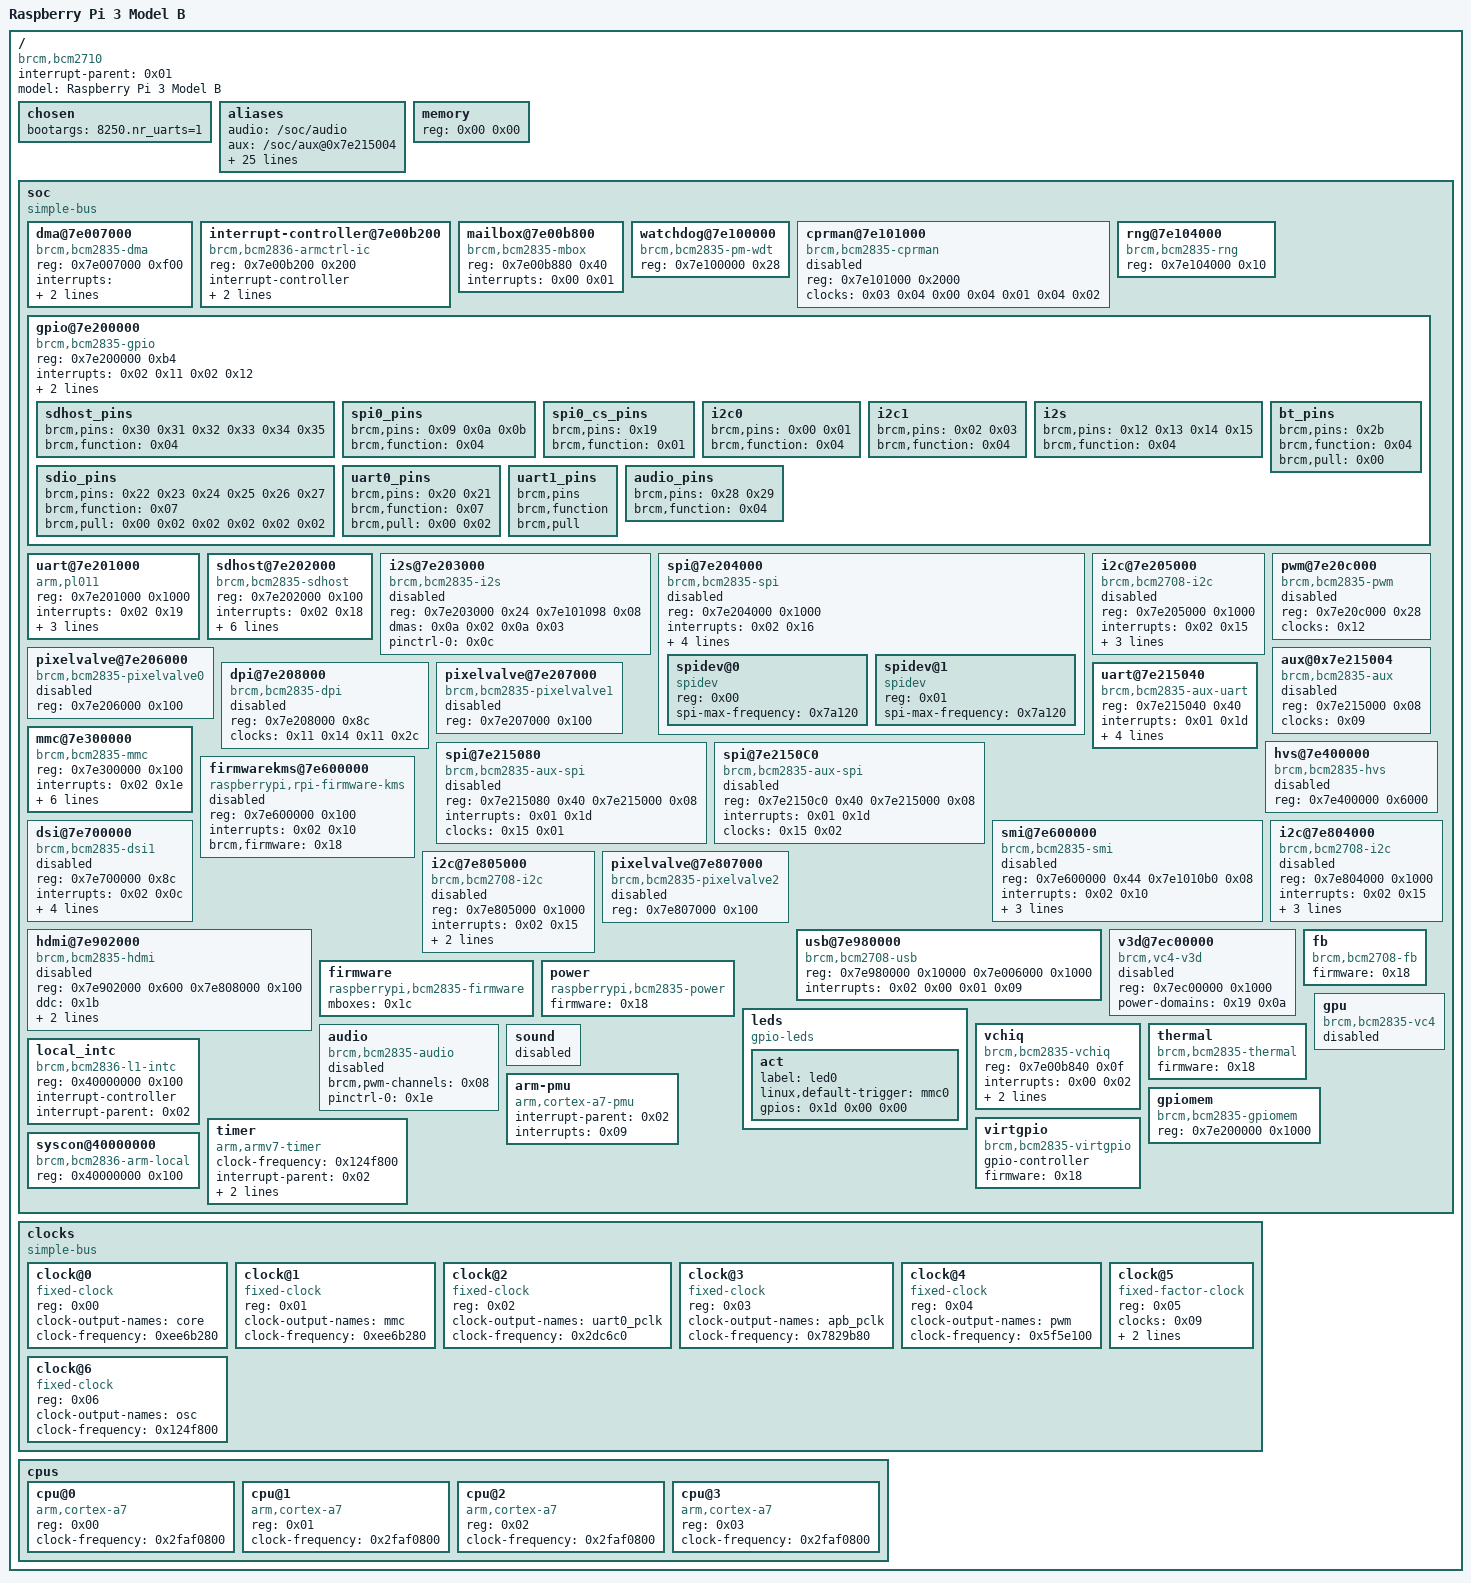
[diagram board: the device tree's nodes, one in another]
/dts-v1/;

/ {
	#address-cells = <0x01>;
	#size-cells = <0x01>;
	interrupt-parent = <0x01>;
	compatible = "brcm,bcm2710\0brcm,bcm2709";
	model = "Raspberry Pi 3 Model B";

	chosen {
		bootargs = "8250.nr_uarts=1";
	};

	aliases {
		audio = "/soc/audio";
		aux = "/soc/aux@0x7e215004";
		sound = "/soc/sound";
		soc = "/soc";
		dma = "/soc/dma@7e007000";
		intc = "/soc/interrupt-controller@7e00b200";
		watchdog = "/soc/watchdog@7e100000";
		random = "/soc/rng@7e104000";
		mailbox = "/soc/mailbox@7e00b800";
		gpio = "/soc/gpio@7e200000";
		uart0 = "/soc/uart@7e201000";
		sdhost = "/soc/sdhost@7e202000";
		i2s = "/soc/i2s@7e203000";
		spi0 = "/soc/spi@7e204000";
		i2c0 = "/soc/i2c@7e205000";
		uart1 = "/soc/uart@7e215040";
		spi1 = "/soc/spi@7e215080";
		spi2 = "/soc/spi@7e2150C0";
		mmc = "/soc/mmc@7e300000";
		i2c1 = "/soc/i2c@7e804000";
		i2c2 = "/soc/i2c@7e805000";
		usb = "/soc/usb@7e980000";
		leds = "/soc/leds";
		fb = "/soc/fb";
		vchiq = "/soc/vchiq";
		thermal = "/soc/thermal";
		clocks = "/clocks";
	};

	memory {
		device_type = "memory";
		reg = <0x00 0x00>;
	};

	soc {
		compatible = "simple-bus";
		#address-cells = <0x01>;
		#size-cells = <0x01>;
		ranges = <0x7e000000 0x3f000000 0x1000000 0x40000000 0x40000000 0x40000>;
		phandle = <0x2f>;

		dma@7e007000 {
			compatible = "brcm,bcm2835-dma";
			reg = <0x7e007000 0xf00>;
			interrupts = <0x01 0x10 0x01 0x11 0x01 0x12 0x01 0x13 0x01 0x14 0x01 0x15 0x01 0x16 0x01 0x17 0x01 0x18 0x01 0x19 0x01 0x1a 0x01 0x1b 0x01 0x1b 0x01 0x1b 0x01 0x1b 0x01 0x1c>;
			interrupt-names = "dma0\0dma1\0dma2\0dma3\0dma4\0dma5\0dma6\0dma7\0dma8\0dma9\0dma10\0dma11\0dma12\0dma13\0dma14\0dma-shared-all";
			#dma-cells = <0x01>;
			brcm,dma-channel-mask = <0x7f34>;
			phandle = <0x0a>;
		};

		interrupt-controller@7e00b200 {
			compatible = "brcm,bcm2836-armctrl-ic";
			reg = <0x7e00b200 0x200>;
			interrupt-controller;
			#interrupt-cells = <0x02>;
			interrupt-parent = <0x02>;
			interrupts = <0x08>;
			phandle = <0x01>;
		};

		mailbox@7e00b800 {
			compatible = "brcm,bcm2835-mbox";
			reg = <0x7e00b880 0x40>;
			interrupts = <0x00 0x01>;
			#mbox-cells = <0x00>;
			phandle = <0x1c>;
		};

		watchdog@7e100000 {
			compatible = "brcm,bcm2835-pm-wdt";
			reg = <0x7e100000 0x28>;
			status = "okay";
			phandle = <0x2c>;
		};

		cprman@7e101000 {
			compatible = "brcm,bcm2835-cprman";
			#clock-cells = <0x01>;
			reg = <0x7e101000 0x2000>;
			clocks = <0x03 0x04 0x00 0x04 0x01 0x04 0x02>;
			status = "disabled";
			phandle = <0x11>;
		};

		rng@7e104000 {
			compatible = "brcm,bcm2835-rng";
			reg = <0x7e104000 0x10>;
			status = "okay";
			phandle = <0x2d>;
		};

		gpio@7e200000 {
			compatible = "brcm,bcm2835-gpio";
			reg = <0x7e200000 0xb4>;
			interrupts = <0x02 0x11 0x02 0x12>;
			gpio-controller;
			#gpio-cells = <0x02>;
			interrupt-controller;
			#interrupt-cells = <0x02>;
			phandle = <0x0d>;

			sdhost_pins {
				brcm,pins = <0x30 0x31 0x32 0x33 0x34 0x35>;
				brcm,function = <0x04>;
				phandle = <0x0b>;
			};

			spi0_pins {
				brcm,pins = <0x09 0x0a 0x0b>;
				brcm,function = <0x04>;
				phandle = <0x0e>;
			};

			spi0_cs_pins {
				brcm,pins = <0x19>;
				brcm,function = <0x01>;
				phandle = <0x0f>;
			};

			i2c0 {
				brcm,pins = <0x00 0x01>;
				brcm,function = <0x04>;
				phandle = <0x10>;
			};

			i2c1 {
				brcm,pins = <0x02 0x03>;
				brcm,function = <0x04>;
				phandle = <0x1a>;
			};

			i2s {
				brcm,pins = <0x12 0x13 0x14 0x15>;
				brcm,function = <0x04>;
				phandle = <0x0c>;
			};

			sdio_pins {
				brcm,pins = <0x22 0x23 0x24 0x25 0x26 0x27>;
				brcm,function = <0x07>;
				brcm,pull = <0x00 0x02 0x02 0x02 0x02 0x02>;
				phandle = <0x17>;
			};

			bt_pins {
				brcm,pins = <0x2b>;
				brcm,function = <0x04>;
				brcm,pull = <0x00>;
				phandle = <0x08>;
			};

			uart0_pins {
				brcm,pins = <0x20 0x21>;
				brcm,function = <0x07>;
				brcm,pull = <0x00 0x02>;
				phandle = <0x07>;
			};

			uart1_pins {
				brcm,pins;
				brcm,function;
				brcm,pull;
				phandle = <0x14>;
			};

			audio_pins {
				brcm,pins = <0x28 0x29>;
				brcm,function = <0x04>;
				phandle = <0x1e>;
			};
		};

		uart@7e201000 {
			compatible = "arm,pl011\0arm,primecell";
			reg = <0x7e201000 0x1000>;
			interrupts = <0x02 0x19>;
			clocks = <0x05 0x06>;
			clock-names = "uartclk\0apb_pclk";
			arm,primecell-periphid = <0x241011>;
			status = "okay";
			pinctrl-names = "default";
			pinctrl-0 = <0x07 0x08>;
			phandle = <0x24>;
		};

		sdhost@7e202000 {
			compatible = "brcm,bcm2835-sdhost";
			reg = <0x7e202000 0x100>;
			interrupts = <0x02 0x18>;
			clocks = <0x09>;
			dmas = <0x0a 0x0d>;
			dma-names = "rx-tx";
			brcm,overclock-50 = <0x00>;
			brcm,pio-limit = <0x01>;
			status = "okay";
			pinctrl-names = "default";
			pinctrl-0 = <0x0b>;
			bus-width = <0x04>;
			phandle = <0x2e>;
		};

		i2s@7e203000 {
			compatible = "brcm,bcm2835-i2s";
			#sound-dai-cells = <0x00>;
			reg = <0x7e203000 0x24 0x7e101098 0x08>;
			dmas = <0x0a 0x02 0x0a 0x03>;
			dma-names = "tx\0rx";
			status = "disabled";
			pinctrl-names = "default";
			pinctrl-0 = <0x0c>;
			phandle = <0x26>;
		};

		spi@7e204000 {
			compatible = "brcm,bcm2835-spi";
			reg = <0x7e204000 0x1000>;
			interrupts = <0x02 0x16>;
			clocks = <0x09>;
			#address-cells = <0x01>;
			#size-cells = <0x00>;
			status = "disabled";
			dmas = <0x0a 0x06 0x0a 0x07>;
			dma-names = "tx\0rx";
			cs-gpios = <0x0d 0x08 0x01 0x0d 0x07 0x01>;
			pinctrl-names = "default";
			pinctrl-0 = <0x0e 0x0f>;
			phandle = <0x27>;

			spidev@0 {
				compatible = "spidev";
				reg = <0x00>;
				#address-cells = <0x01>;
				#size-cells = <0x00>;
				spi-max-frequency = <0x7a120>;
				phandle = <0x30>;
			};

			spidev@1 {
				compatible = "spidev";
				reg = <0x01>;
				#address-cells = <0x01>;
				#size-cells = <0x00>;
				spi-max-frequency = <0x7a120>;
				phandle = <0x31>;
			};
		};

		i2c@7e205000 {
			compatible = "brcm,bcm2708-i2c";
			reg = <0x7e205000 0x1000>;
			interrupts = <0x02 0x15>;
			clocks = <0x09>;
			#address-cells = <0x01>;
			#size-cells = <0x00>;
			status = "disabled";
			pinctrl-names = "default";
			pinctrl-0 = <0x10>;
			clock-frequency = <0x186a0>;
			phandle = <0x28>;
		};

		pixelvalve@7e206000 {
			compatible = "brcm,bcm2835-pixelvalve0";
			reg = <0x7e206000 0x100>;
			status = "disabled";
			phandle = <0x32>;
		};

		dpi@7e208000 {
			compatible = "brcm,bcm2835-dpi";
			reg = <0x7e208000 0x8c>;
			clocks = <0x11 0x14 0x11 0x2c>;
			clock-names = "core\0pixel";
			#address-cells = <0x01>;
			#size-cells = <0x00>;
			status = "disabled";
			phandle = <0x33>;
		};

		pixelvalve@7e207000 {
			compatible = "brcm,bcm2835-pixelvalve1";
			reg = <0x7e207000 0x100>;
			status = "disabled";
			phandle = <0x34>;
		};

		pwm@7e20c000 {
			compatible = "brcm,bcm2835-pwm";
			reg = <0x7e20c000 0x28>;
			clocks = <0x12>;
			#pwm-cells = <0x02>;
			status = "disabled";
			phandle = <0x35>;
		};

		aux@0x7e215004 {
			compatible = "brcm,bcm2835-aux";
			#clock-cells = <0x01>;
			reg = <0x7e215000 0x08>;
			clocks = <0x09>;
			status = "disabled";
			phandle = <0x15>;
		};

		uart@7e215040 {
			compatible = "brcm,bcm2835-aux-uart\0ns16550";
			reg = <0x7e215040 0x40>;
			interrupts = <0x01 0x1d>;
			clocks = <0x13>;
			reg-shift = <0x02>;
			no-loopback-test;
			status = "okay";
			pinctrl-names = "default";
			pinctrl-0 = <0x14>;
			phandle = <0x25>;
		};

		spi@7e215080 {
			compatible = "brcm,bcm2835-aux-spi";
			reg = <0x7e215080 0x40 0x7e215000 0x08>;
			interrupts = <0x01 0x1d>;
			clocks = <0x15 0x01>;
			#address-cells = <0x01>;
			#size-cells = <0x00>;
			status = "disabled";
			phandle = <0x36>;
		};

		spi@7e2150C0 {
			compatible = "brcm,bcm2835-aux-spi";
			reg = <0x7e2150c0 0x40 0x7e215000 0x08>;
			interrupts = <0x01 0x1d>;
			clocks = <0x15 0x02>;
			#address-cells = <0x01>;
			#size-cells = <0x00>;
			status = "disabled";
			phandle = <0x37>;
		};

		mmc@7e300000 {
			compatible = "brcm,bcm2835-mmc";
			reg = <0x7e300000 0x100>;
			interrupts = <0x02 0x1e>;
			clocks = <0x16>;
			dmas = <0x0a 0x0b>;
			dma-names = "rx-tx";
			brcm,overclock-50 = <0x00>;
			status = "okay";
			pinctrl-names = "default";
			pinctrl-0 = <0x17>;
			non-removable;
			bus-width = <0x04>;
			phandle = <0x38>;
		};

		hvs@7e400000 {
			compatible = "brcm,bcm2835-hvs";
			reg = <0x7e400000 0x6000>;
			status = "disabled";
			phandle = <0x39>;
		};

		firmwarekms@7e600000 {
			compatible = "raspberrypi,rpi-firmware-kms";
			reg = <0x7e600000 0x100>;
			interrupts = <0x02 0x10>;
			brcm,firmware = <0x18>;
			status = "disabled";
			phandle = <0x3a>;
		};

		smi@7e600000 {
			compatible = "brcm,bcm2835-smi";
			reg = <0x7e600000 0x44 0x7e1010b0 0x08>;
			interrupts = <0x02 0x10>;
			brcm,smi-clock-source = <0x06>;
			brcm,smi-clock-divisor = <0x04>;
			dmas = <0x0a 0x04>;
			dma-names = "rx-tx";
			status = "disabled";
			phandle = <0x3b>;
		};

		dsi@7e700000 {
			#address-cells = <0x01>;
			#size-cells = <0x00>;
			#clock-cells = <0x01>;
			compatible = "brcm,bcm2835-dsi1";
			reg = <0x7e700000 0x8c>;
			interrupts = <0x02 0x0c>;
			clocks = <0x11 0x23 0x11 0x30 0x11 0x31>;
			clock-names = "phy\0escape\0pixel";
			clock-output-names = "dsi1_byte\0dsi1_ddr2\0dsi1_ddr";
			status = "disabled";
			power-domains = <0x19 0x12>;
			phandle = <0x04>;
		};

		i2c@7e804000 {
			compatible = "brcm,bcm2708-i2c";
			reg = <0x7e804000 0x1000>;
			interrupts = <0x02 0x15>;
			clocks = <0x09>;
			#address-cells = <0x01>;
			#size-cells = <0x00>;
			status = "disabled";
			pinctrl-names = "default";
			pinctrl-0 = <0x1a>;
			clock-frequency = <0x186a0>;
			phandle = <0x29>;
		};

		i2c@7e805000 {
			compatible = "brcm,bcm2708-i2c";
			reg = <0x7e805000 0x1000>;
			interrupts = <0x02 0x15>;
			clocks = <0x09>;
			#address-cells = <0x01>;
			#size-cells = <0x00>;
			status = "disabled";
			clock-frequency = <0x186a0>;
			phandle = <0x1b>;
		};

		pixelvalve@7e807000 {
			compatible = "brcm,bcm2835-pixelvalve2";
			reg = <0x7e807000 0x100>;
			status = "disabled";
			phandle = <0x3c>;
		};

		hdmi@7e902000 {
			compatible = "brcm,bcm2835-hdmi";
			reg = <0x7e902000 0x600 0x7e808000 0x100>;
			ddc = <0x1b>;
			clocks = <0x11 0x10 0x11 0x19>;
			clock-names = "pixel\0hdmi";
			power-domains = <0x19 0x05>;
			status = "disabled";
			phandle = <0x3d>;
		};

		usb@7e980000 {
			compatible = "brcm,bcm2708-usb";
			reg = <0x7e980000 0x10000 0x7e006000 0x1000>;
			interrupts = <0x02 0x00 0x01 0x09>;
			phandle = <0x3e>;
		};

		v3d@7ec00000 {
			compatible = "brcm,vc4-v3d";
			reg = <0x7ec00000 0x1000>;
			power-domains = <0x19 0x0a>;
			status = "disabled";
			phandle = <0x3f>;
		};

		firmware {
			compatible = "raspberrypi,bcm2835-firmware";
			mboxes = <0x1c>;
			phandle = <0x18>;
		};

		power {
			compatible = "raspberrypi,bcm2835-power";
			firmware = <0x18>;
			#power-domain-cells = <0x01>;
			phandle = <0x19>;
		};

		leds {
			compatible = "gpio-leds";
			phandle = <0x40>;

			act {
				label = "led0";
				linux,default-trigger = "mmc0";
				gpios = <0x1d 0x00 0x00>;
				phandle = <0x2a>;
			};
		};

		fb {
			compatible = "brcm,bcm2708-fb";
			firmware = <0x18>;
			status = "okay";
			phandle = <0x41>;
		};

		vchiq {
			compatible = "brcm,bcm2835-vchiq";
			reg = <0x7e00b840 0x0f>;
			interrupts = <0x00 0x02>;
			cache-line-size = <0x20>;
			firmware = <0x18>;
			phandle = <0x1f>;
		};

		thermal {
			compatible = "brcm,bcm2835-thermal";
			firmware = <0x18>;
			phandle = <0x42>;
		};

		gpu {
			compatible = "brcm,bcm2835-vc4";
			status = "disabled";
			phandle = <0x43>;
		};

		audio {
			compatible = "brcm,bcm2835-audio";
			brcm,pwm-channels = <0x08>;
			status = "disabled";
			pinctrl-names = "default";
			pinctrl-0 = <0x1e>;
			phandle = <0x2b>;
		};

		sound {
			status = "disabled";
			phandle = <0x44>;
		};

		local_intc {
			compatible = "brcm,bcm2836-l1-intc";
			reg = <0x40000000 0x100>;
			interrupt-controller;
			#interrupt-cells = <0x01>;
			interrupt-parent = <0x02>;
			phandle = <0x02>;
		};

		arm-pmu {
			compatible = "arm,cortex-a7-pmu";
			interrupt-parent = <0x02>;
			interrupts = <0x09>;
		};

		gpiomem {
			compatible = "brcm,bcm2835-gpiomem";
			reg = <0x7e200000 0x1000>;
			status = "okay";
		};

		timer {
			compatible = "arm,armv7-timer";
			clock-frequency = <0x124f800>;
			interrupt-parent = <0x02>;
			interrupts = <0x00 0x01 0x03 0x02>;
			always-on;
		};

		syscon@40000000 {
			compatible = "brcm,bcm2836-arm-local\0syscon";
			reg = <0x40000000 0x100>;
		};

		virtgpio {
			compatible = "brcm,bcm2835-virtgpio";
			gpio-controller;
			#gpio-cells = <0x02>;
			firmware = <0x18>;
			status = "okay";
			phandle = <0x1d>;
		};
	};

	clocks {
		compatible = "simple-bus";
		#address-cells = <0x01>;
		#size-cells = <0x00>;
		phandle = <0x45>;

		clock@0 {
			compatible = "fixed-clock";
			reg = <0x00>;
			#clock-cells = <0x00>;
			clock-output-names = "core";
			clock-frequency = <0xee6b280>;
			phandle = <0x09>;
		};

		clock@1 {
			compatible = "fixed-clock";
			reg = <0x01>;
			#clock-cells = <0x00>;
			clock-output-names = "mmc";
			clock-frequency = <0xee6b280>;
			phandle = <0x16>;
		};

		clock@2 {
			compatible = "fixed-clock";
			reg = <0x02>;
			#clock-cells = <0x00>;
			clock-output-names = "uart0_pclk";
			clock-frequency = <0x2dc6c0>;
			phandle = <0x05>;
		};

		clock@3 {
			compatible = "fixed-clock";
			reg = <0x03>;
			#clock-cells = <0x00>;
			clock-output-names = "apb_pclk";
			clock-frequency = <0x7829b80>;
			phandle = <0x06>;
		};

		clock@4 {
			compatible = "fixed-clock";
			reg = <0x04>;
			#clock-cells = <0x00>;
			clock-output-names = "pwm";
			clock-frequency = <0x5f5e100>;
			phandle = <0x12>;
		};

		clock@5 {
			compatible = "fixed-factor-clock";
			reg = <0x05>;
			clocks = <0x09>;
			#clock-cells = <0x00>;
			clock-div = <0x01>;
			clock-mult = <0x02>;
			phandle = <0x13>;
		};

		clock@6 {
			compatible = "fixed-clock";
			reg = <0x06>;
			#clock-cells = <0x00>;
			clock-output-names = "osc";
			clock-frequency = <0x124f800>;
			phandle = <0x03>;
		};
	};

	__overrides__ {
		cache_line_size = [00 00 00 1f 63 61 63 68 65 2d 6c 69 6e 65 2d 73 69 7a 65 3a 30 00];
		arm_freq = "\0\0\0 clock-frequency:0\0\0\0\0!clock-frequency:0\0\0\0\0\"clock-frequency:0\0\0\0\0#clock-frequency:0";
		uart0 = "\0\0\0$status";
		uart0_clkrate = [00 00 00 05 63 6c 6f 63 6b 2d 66 72 65 71 75 65 6e 63 79 3a 30 00];
		uart1 = "\0\0\0%status";
		i2s = "\0\0\0&status";
		spi = "\0\0\0'status";
		i2c0 = "\0\0\0(status";
		i2c1 = "\0\0\0)status";
		i2c2_iknowwhatimdoing = [00 00 00 1b 73 74 61 74 75 73 00];
		i2c0_baudrate = "\0\0\0(clock-frequency:0";
		i2c1_baudrate = "\0\0\0)clock-frequency:0";
		i2c2_baudrate = [00 00 00 1b 63 6c 6f 63 6b 2d 66 72 65 71 75 65 6e 63 79 3a 30 00];
		core_freq = "\0\0\0\tclock-frequency:0";
		act_led_gpio = "\0\0\0*gpios:4";
		act_led_activelow = "\0\0\0*gpios:8";
		act_led_trigger = "\0\0\0*linux,default-trigger";
		audio = "\0\0\0+status";
		watchdog = "\0\0\0,status";
		random = "\0\0\0-status";
		sd_overclock = "\0\0\0.brcm,overclock-50:0";
		sd_force_pio = "\0\0\0.brcm,force-pio?";
		sd_pio_limit = "\0\0\0.brcm,pio-limit:0";
		sd_debug = "\0\0\0.brcm,debug";
	};

	cpus {
		#address-cells = <0x01>;
		#size-cells = <0x00>;
		phandle = <0x46>;

		cpu@0 {
			device_type = "cpu";
			compatible = "arm,cortex-a7";
			reg = <0x00>;
			clock-frequency = <0x2faf0800>;
			phandle = <0x20>;
		};

		cpu@1 {
			device_type = "cpu";
			compatible = "arm,cortex-a7";
			reg = <0x01>;
			clock-frequency = <0x2faf0800>;
			phandle = <0x21>;
		};

		cpu@2 {
			device_type = "cpu";
			compatible = "arm,cortex-a7";
			reg = <0x02>;
			clock-frequency = <0x2faf0800>;
			phandle = <0x22>;
		};

		cpu@3 {
			device_type = "cpu";
			compatible = "arm,cortex-a7";
			reg = <0x03>;
			clock-frequency = <0x2faf0800>;
			phandle = <0x23>;
		};
	};

	__symbols__ {
		soc = "/soc";
		dma = "/soc/dma@7e007000";
		intc = "/soc/interrupt-controller@7e00b200";
		mailbox = "/soc/mailbox@7e00b800";
		watchdog = "/soc/watchdog@7e100000";
		cprman = "/soc/cprman@7e101000";
		random = "/soc/rng@7e104000";
		gpio = "/soc/gpio@7e200000";
		sdhost_pins = "/soc/gpio@7e200000/sdhost_pins";
		spi0_pins = "/soc/gpio@7e200000/spi0_pins";
		spi0_cs_pins = "/soc/gpio@7e200000/spi0_cs_pins";
		i2c0_pins = "/soc/gpio@7e200000/i2c0";
		i2c1_pins = "/soc/gpio@7e200000/i2c1";
		i2s_pins = "/soc/gpio@7e200000/i2s";
		sdio_pins = "/soc/gpio@7e200000/sdio_pins";
		bt_pins = "/soc/gpio@7e200000/bt_pins";
		uart0_pins = "/soc/gpio@7e200000/uart0_pins";
		uart1_pins = "/soc/gpio@7e200000/uart1_pins";
		audio_pins = "/soc/gpio@7e200000/audio_pins";
		uart0 = "/soc/uart@7e201000";
		sdhost = "/soc/sdhost@7e202000";
		i2s = "/soc/i2s@7e203000";
		spi0 = "/soc/spi@7e204000";
		spidev0 = "/soc/spi@7e204000/spidev@0";
		spidev1 = "/soc/spi@7e204000/spidev@1";
		i2c0 = "/soc/i2c@7e205000";
		pixelvalve0 = "/soc/pixelvalve@7e206000";
		dpi = "/soc/dpi@7e208000";
		pixelvalve1 = "/soc/pixelvalve@7e207000";
		pwm = "/soc/pwm@7e20c000";
		aux = "/soc/aux@0x7e215004";
		uart1 = "/soc/uart@7e215040";
		spi1 = "/soc/spi@7e215080";
		spi2 = "/soc/spi@7e2150C0";
		mmc = "/soc/mmc@7e300000";
		hvs = "/soc/hvs@7e400000";
		firmwarekms = "/soc/firmwarekms@7e600000";
		smi = "/soc/smi@7e600000";
		dsi1 = "/soc/dsi@7e700000";
		i2c1 = "/soc/i2c@7e804000";
		i2c2 = "/soc/i2c@7e805000";
		pixelvalve2 = "/soc/pixelvalve@7e807000";
		hdmi = "/soc/hdmi@7e902000";
		usb = "/soc/usb@7e980000";
		v3d = "/soc/v3d@7ec00000";
		firmware = "/soc/firmware";
		power = "/soc/power";
		leds = "/soc/leds";
		act_led = "/soc/leds/act";
		fb = "/soc/fb";
		vchiq = "/soc/vchiq";
		thermal = "/soc/thermal";
		gpu = "/soc/gpu";
		audio = "/soc/audio";
		sound = "/soc/sound";
		local_intc = "/soc/local_intc";
		virtgpio = "/soc/virtgpio";
		clocks = "/clocks";
		clk_core = "/clocks/clock@0";
		clk_mmc = "/clocks/clock@1";
		clk_uart0 = "/clocks/clock@2";
		clk_apb_p = "/clocks/clock@3";
		clk_pwm = "/clocks/clock@4";
		clk_uart1 = "/clocks/clock@5";
		clk_osc = "/clocks/clock@6";
		cpus = "/cpus";
		v7_cpu0 = "/cpus/cpu@0";
		v7_cpu1 = "/cpus/cpu@1";
		v7_cpu2 = "/cpus/cpu@2";
		v7_cpu3 = "/cpus/cpu@3";
	};
};
